# f28p65x_epwm_xcmp_regs register map
Vendor: Texas Instruments
Peripheral module from a debugger description file (folder C2000).
Address unit: 16 bits
Registers are 32-bit, read-write, no defined reset value unless marked. A register's access mark holds for its fields unless they carry their own. Offsets are as the file gives them; lines under a group give offsets from that group; [hi:lo] are bit positions; {n}, {i} and the like mark numbered series; 'fields as' and 'values as' point back to an identical list; <NAME> marks a mode.

## EPWM_XCMP_REGS — EPWM XCMP Registers
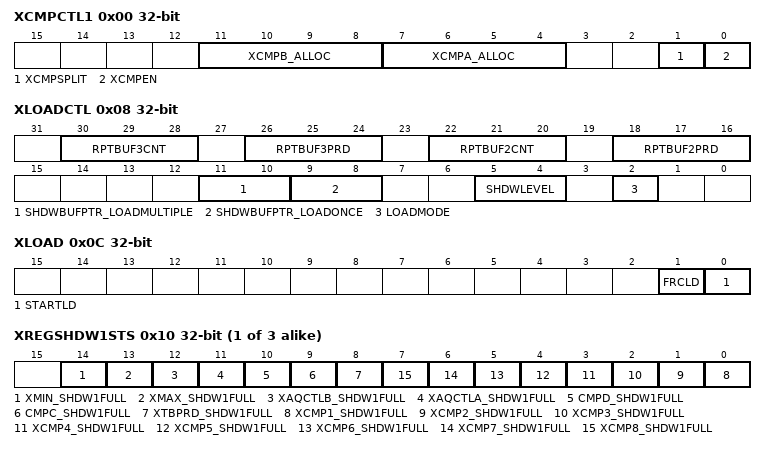
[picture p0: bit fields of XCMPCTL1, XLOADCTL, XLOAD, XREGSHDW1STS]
0x00 XCMPCTL1 — XCMP Mode Control Register
  [11:8] XCMPB_ALLOC — XCMPn register allocation for CMPB
  [7:4] XCMPA_ALLOC — XCMPn register allocation for CMPA
  [1] XCMPSPLIT — XCMP Register Allocation Options
  [0] XCMPEN — XCMP Compare Register Operation Enable
0x08 XLOADCTL access per field — XCMP Mode Load Control Register
  [30:28] RPTBUF3CNT ro — Repeat Count Status Shadow Buffer 3
  [26:24] RPTBUF3PRD rw — Repeat Count Shadow Buffer 3
  [22:20] RPTBUF2CNT ro — Repeat Count Status Shadow Buffer 2
  [18:16] RPTBUF2PRD rw — Repeat Count Shadow Buffer 2
  [11:10] SHDWBUFPTR_LOADMULTIPLE ro — Register Load event count
  [9:8] SHDWBUFPTR_LOADONCE rw — Register Load event count
  [5:4] SHDWLEVEL rw — Shadow Register Level Allocation Options
  [2] LOADMODE rw — Load mode selection for Shadow registers
0x0C XLOAD — XCMP Mode Load Enable Register
  [1] FRCLD — Force register loading of shadow buffers
  [0] STARTLD — Enable register loading of shadow buffers
0x0E EPWMXLINKXLOAD — Link register across PWM modules
  [4:0] XLOADLINK
{0xC+4i} XREGSHDW{i}STS ro (i=1..3) — Shadow Buffer {i} Update Status Register
  [14] XMIN_SHDW{i}FULL — XMINMAX_SHDW{i} register full Status flag: MIN field update
  [13] XMAX_SHDW{i}FULL — XMINMAX_SHDW{i} register full Status flag:MAX field update
  [12] XAQCTLB_SHDW{i}FULL — XAQCTLB_SHDW{i} register full Status flag:
  [11] XAQCTLA_SHDW{i}FULL — XAQCTLA_SHDW{i} register full Status flag:
  [10] CMPD_SHDW{i}FULL — CMPD_SHDW{i} register full Status flag:
  [9] CMPC_SHDW{i}FULL — CMPC_SHDW{i} register full Status flag:
  [8] XTBPRD_SHDW{i}FULL — XTBPRD_SHDW{i} register full Status flag:
  [n-1] XCMP{n}_SHDW{i}FULL (n=1..8) — XCMP{n}_SHDW{i} register full Status flag
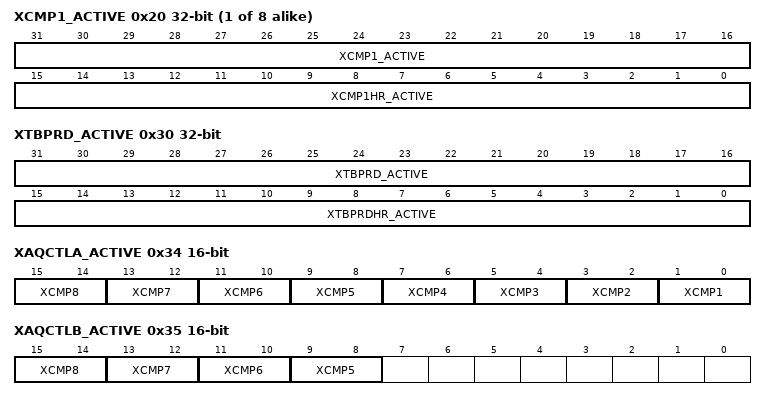
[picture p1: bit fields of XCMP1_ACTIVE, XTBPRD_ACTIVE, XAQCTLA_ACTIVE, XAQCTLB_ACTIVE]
{0x1E+2i} XCMP{i}_ACTIVE (i=1..8) — Additional Compare {i} Active Register
  [31:16] XCMP{i}_ACTIVE — Additional Compare {i} Active Register
  [15:0] XCMP{i}HR_ACTIVE — Additional Compare {i} Active HR Register
0x30 XTBPRD_ACTIVE — Additional Time Base Period Active Register
  [31:16] XTBPRD_ACTIVE — Additional Time Base Period Active Register
  [15:0] XTBPRDHR_ACTIVE — Additional Time Base Period Active HR Register
0x34 XAQCTLA_ACTIVE 16-bit — AQCTLA Active Register
  [2n-1:2n-2] XCMP{n} (n=1..8) — XCMP{n} Action
0x35 XAQCTLB_ACTIVE 16-bit — AQCTLB Active Register
  [2n-1:2n-2] XCMP{n} (n=5..8) — XCMP{n} Action
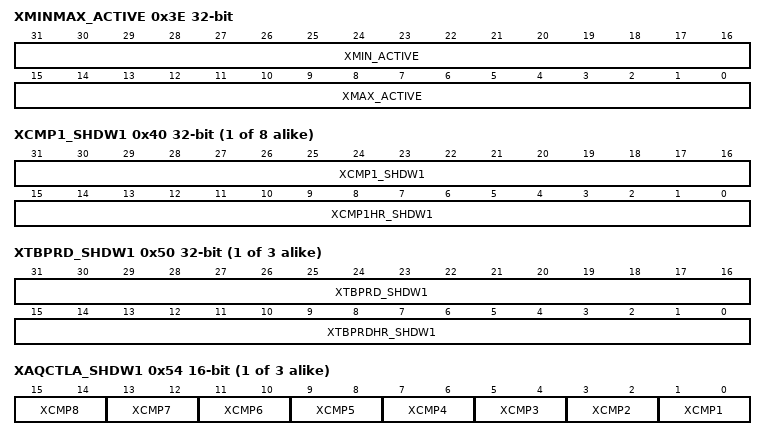
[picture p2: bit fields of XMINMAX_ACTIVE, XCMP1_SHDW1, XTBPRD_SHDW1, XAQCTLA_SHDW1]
0x3E XMINMAX_ACTIVE
  [31:16] XMIN_ACTIVE — Minimum Valude for Capture Counter Active Register
  [15:0] XMAX_ACTIVE — Maximum Valude for Capture Counter Active Register
{0x3E+2i} XCMP{i}_SHDW1 (i=1..8) — Additional Compare {i} Shadow 1 Register
  [31:16] XCMP{i}_SHDW1 — Additional Compare {i} Shadow 1 Register
  [15:0] XCMP{i}HR_SHDW1 — Additional Compare {i} Shadow 1 HR Register
{0x30+0x20*i} XTBPRD_SHDW{i} (i=1..3) — Additional Time Base Period Shadow {i} Register
  [31:16] XTBPRD_SHDW{i} — Additional Time Base Period Shadow 1 Register
  [15:0] XTBPRDHR_SHDW{i} — Additional Time Base Period Shadow 1 HR Register
{0x34+0x20*i} XAQCTLA_SHDW{i} 16-bit (i=1..3) — XAQCTLA Shadow {i} Register
  [2n-1:2n-2] XCMP{n} (n=1..8) — XCMP{n} Action
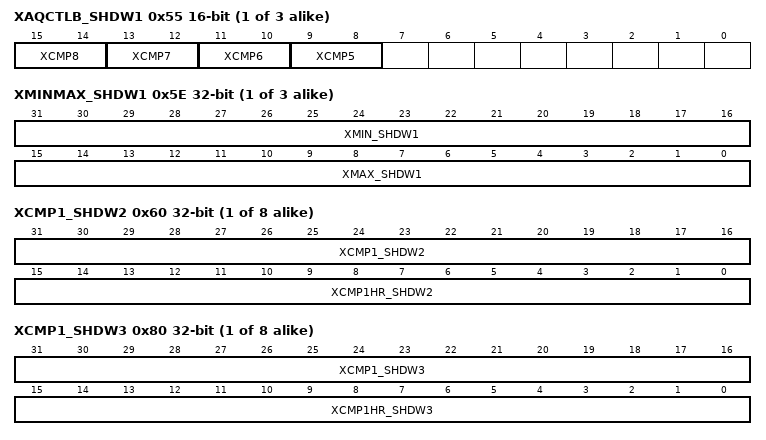
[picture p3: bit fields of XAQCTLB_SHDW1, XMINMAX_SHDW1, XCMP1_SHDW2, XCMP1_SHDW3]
{0x35+0x20*i} XAQCTLB_SHDW{i} 16-bit (i=1..3) — XAQCTLB Shadow {i} Register
  [2n-1:2n-2] XCMP{n} (n=5..8) — XCMP{n} Action
{0x37+0x20*i} CMPC_SHDW{i} 16-bit (i=1..3) — CMPC Shadow {i} Register
{0x39+0x20*i} CMPD_SHDW{i} 16-bit (i=1..3) — CMPD Shadow {i} Register
{0x3E+0x20*i} XMINMAX_SHDW{i} (i=1..3) — XMINMAX Shadow {i} Register
  [31:16] XMIN_SHDW{i} — Minimum Valude for Capture Counter Active Register
  [15:0] XMAX_SHDW{i} — Maximum Valude for Capture Counter Active Register
{0x5E+2i} XCMP{i}_SHDW2 (i=1..8) — Additional Compare {i} Shadow 2 Register
  [31:16] XCMP{i}_SHDW2 — Additional Compare {i} Shadow 2 Register
  [15:0] XCMP{i}HR_SHDW2 — Additional Compare {i} Shadow 2 HR Register
{0x7E+2i} XCMP{i}_SHDW3 (i=1..8) — Additional Compare {i} Shadow 3 Register
  [31:16] XCMP{i}_SHDW3 — Additional Compare {i} Shadow 3 Register
  [15:0] XCMP{i}HR_SHDW3 — Additional Compare {i} Shadow 3 HR Register
